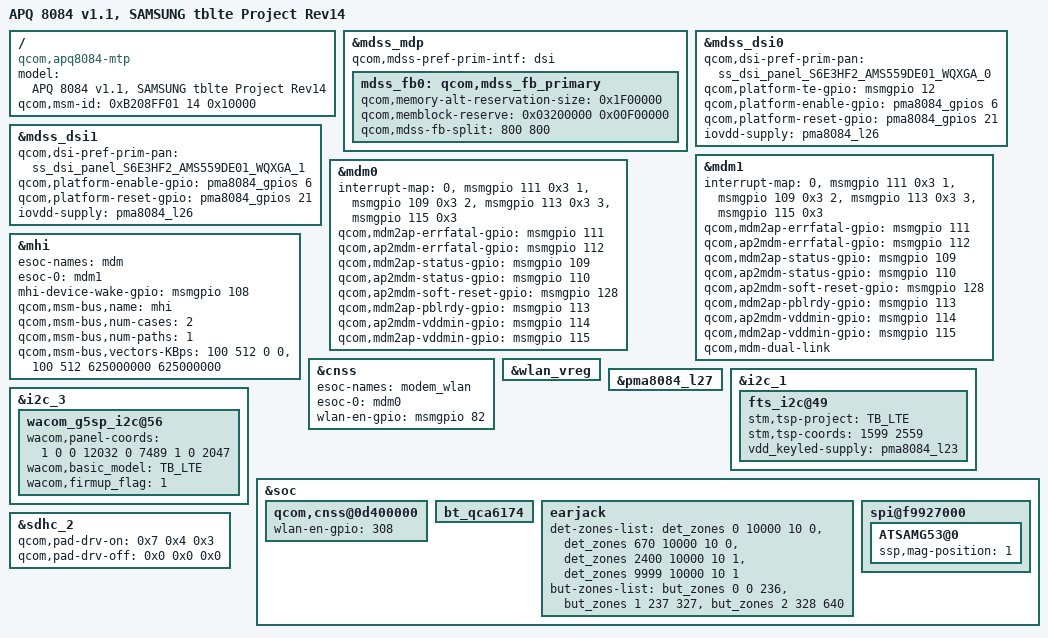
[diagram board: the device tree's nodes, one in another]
/* Copyright (c) 2013-2014, The Linux Foundation. All rights reserved.
 *
 * This program is free software; you can redistribute it and/or modify
 * it under the terms of the GNU General Public License version 2 and
 * only version 2 as published by the Free Software Foundation.
 *
 * This program is distributed in the hope that it will be useful,
 * but WITHOUT ANY WARRANTY; without even the implied warranty of
 * MERCHANTABILITY or FITNESS FOR A PARTICULAR PURPOSE.  See the
 * GNU General Public License for more details.
 */

/dts-v1/;

/memreserve/ 0xac1c0000 0x00001000;
/memreserve/ 0x00000000 0x00001000;

#include "apq8084-v1.1.dtsi"
#include "apq8084-mtp.dtsi"

/* CAUTIONS : TBLTE are referring the TRLTE dtsi */
#include "apq8084-sii8620-mhl3-tblte-r06.dtsi"
#include "apq8084-sec-trlte-r14.dtsi"
#include "apq8084-sec-tblte-battery-r09.dtsi"
/ {
	model = "APQ 8084 v1.1, SAMSUNG tblte Project Rev14";
	compatible = "qcom,apq8084-mtp", "qcom,apq8084", "qcom,mtp";
    qcom,msm-id = <0xB208FF01 14 0x10000>;
    /* [31:24] chip-id, [23:16] platform-id, [15:8] national code, [7:0] operator revision, reserved */
};


#include "../../../../drivers/video/msm/mdss/samsung/S6E3HF2_AMS559DE01/dsi_panel_S6E3HF2_AMS559DE01_wqxga_octa_cmd.dtsi"

&mdss_mdp {
	qcom,mdss-pref-prim-intf = "dsi";

	mdss_fb0: qcom,mdss_fb_primary {
		qcom,memory-alt-reservation-size = <0x1F00000>;
		qcom,memblock-reserve = <0x03200000 0x00F00000>;
		qcom,mdss-fb-split = <800 800>;
	};
};

&mdss_dsi0 {
	qcom,dsi-pref-prim-pan = <&ss_dsi_panel_S6E3HF2_AMS559DE01_WQXGA_0>;
	qcom,platform-te-gpio = <&msmgpio 12 0>;

	/*qcom,dsi-panel-bias-vreg;*/
	qcom,platform-enable-gpio = <&pma8084_gpios 6 0>;
	qcom,platform-reset-gpio = <&pma8084_gpios 21 0>;

	iovdd-supply = <&pma8084_l26>;
};

&mdss_dsi1 {
	qcom,dsi-pref-prim-pan = <&ss_dsi_panel_S6E3HF2_AMS559DE01_WQXGA_1>;

/*	pinctrl-names = "mdss_default", "mdss_sleep";*/
/*	pinctrl-0 = <&mdss_dsi_active &mdss_dsi_te_active>;*/
/*	pinctrl-1 = <&mdss_dsi_suspend &mdss_dsi_te_suspend>;*/

	/*qcom,dsi-panel-bias-vreg;*/
	qcom,platform-enable-gpio = <&pma8084_gpios 6 0>;
	qcom,platform-reset-gpio = <&pma8084_gpios 21 0>;

	iovdd-supply = <&pma8084_l26>;
};


&mdm1 {
	interrupt-map = <0 &msmgpio 111 0x3
			1 &msmgpio 109 0x3
			2 &msmgpio 113 0x3
			3 &msmgpio 115 0x3>;
	qcom,mdm2ap-errfatal-gpio = <&msmgpio 111 0x00>;
	qcom,ap2mdm-errfatal-gpio = <&msmgpio 112 0x00>;
	qcom,mdm2ap-status-gpio   = <&msmgpio 109 0x00>;
	qcom,ap2mdm-status-gpio   = <&msmgpio 110 0x00>;
	qcom,ap2mdm-soft-reset-gpio = <&msmgpio 128 0x00>;
	qcom,mdm2ap-pblrdy-gpio = <&msmgpio 113 0x00>;
	qcom,ap2mdm-vddmin-gpio = <&msmgpio 114 0x00>;
	qcom,mdm2ap-vddmin-gpio = <&msmgpio 115 0x00>;
	qcom,mdm-dual-link;
	status = "ok";
};

&mdm0 {
	interrupt-map = <0 &msmgpio 111 0x3
			1 &msmgpio 109 0x3
			2 &msmgpio 113 0x3
			3 &msmgpio 115 0x3>;
	qcom,mdm2ap-errfatal-gpio = <&msmgpio 111 0x00>;
	qcom,ap2mdm-errfatal-gpio = <&msmgpio 112 0x00>;
	qcom,mdm2ap-status-gpio   = <&msmgpio 109 0x00>;
	qcom,ap2mdm-status-gpio   = <&msmgpio 110 0x00>;
	qcom,ap2mdm-soft-reset-gpio = <&msmgpio 128 0x00>;
	qcom,mdm2ap-pblrdy-gpio = <&msmgpio 113 0x00>;
	qcom,ap2mdm-vddmin-gpio = <&msmgpio 114 0x00>;
	qcom,mdm2ap-vddmin-gpio = <&msmgpio 115 0x00>;
	status = "ok";
};

&mhi {
	esoc-names = "mdm";
	esoc-0 = <&mdm1>;
	mhi-device-wake-gpio =
		<&msmgpio 108 0>;
	qcom,msm-bus,name = "mhi";
	qcom,msm-bus,num-cases = <2>;
	qcom,msm-bus,num-paths = <1>;
	qcom,msm-bus,vectors-KBps =
		<100 512 0 0>,
		<100 512 625000000 625000000>;
};

&cnss {
	esoc-names = "modem_wlan";
	esoc-0 = <&mdm0>;
	wlan-en-gpio = <&msmgpio 82 0>;
};

&mdss_fb0 {
	qcom,mdss-fb-split = <800 800>;
};

&wlan_vreg {
	/delete-property/ regulator-always-on;
};

&pma8084_l27 {
	/delete-property/ regulator-always-on;
};

&i2c_1 {
	fts_i2c@49 {
		stm,tsp-project = "TB_LTE";
		stm,tsp-coords = <1599 2559>;
		vdd_keyled-supply = <&pma8084_l23>;
	};
};

&i2c_3  {
	wacom_g5sp_i2c@56 {
		wacom,panel-coords = <1 0 0 12032 0 7489 1 0 2047>;
		wacom,basic_model = "TB_LTE";
		wacom,firmup_flag = <1>;
	};
};

&soc {
	qcom,cnss@0d400000 {
		wlan-en-gpio = <308>;
	};

	bt_qca6174 {
		/delete-property/ qca,bt-vdd-pa-supply;
	};
	earjack {
		det-zones-list = <&det_zones 0 10000 10 0>,
						 <&det_zones 670 10000 10 0>,
						 <&det_zones 2400 10000 10 1>,
						 <&det_zones 9999 10000 10 1>;
		but-zones-list = <&but_zones 0 0 236>,
						 <&but_zones 1 237 327>,
						 <&but_zones 2 328 640>;
	};
	spi@f9927000 {
		ATSAMG53@0 {
			ssp,mag-position = <1>;
		};
	};
};

&sdhc_2 {
		qcom,pad-drv-on = <0x7 0x4 0x3>; /* 16mA, 10mA, 8mA */
		qcom,pad-drv-off = <0x0 0x0 0x0>; /* 2mA, 2mA, 2mA */
};

